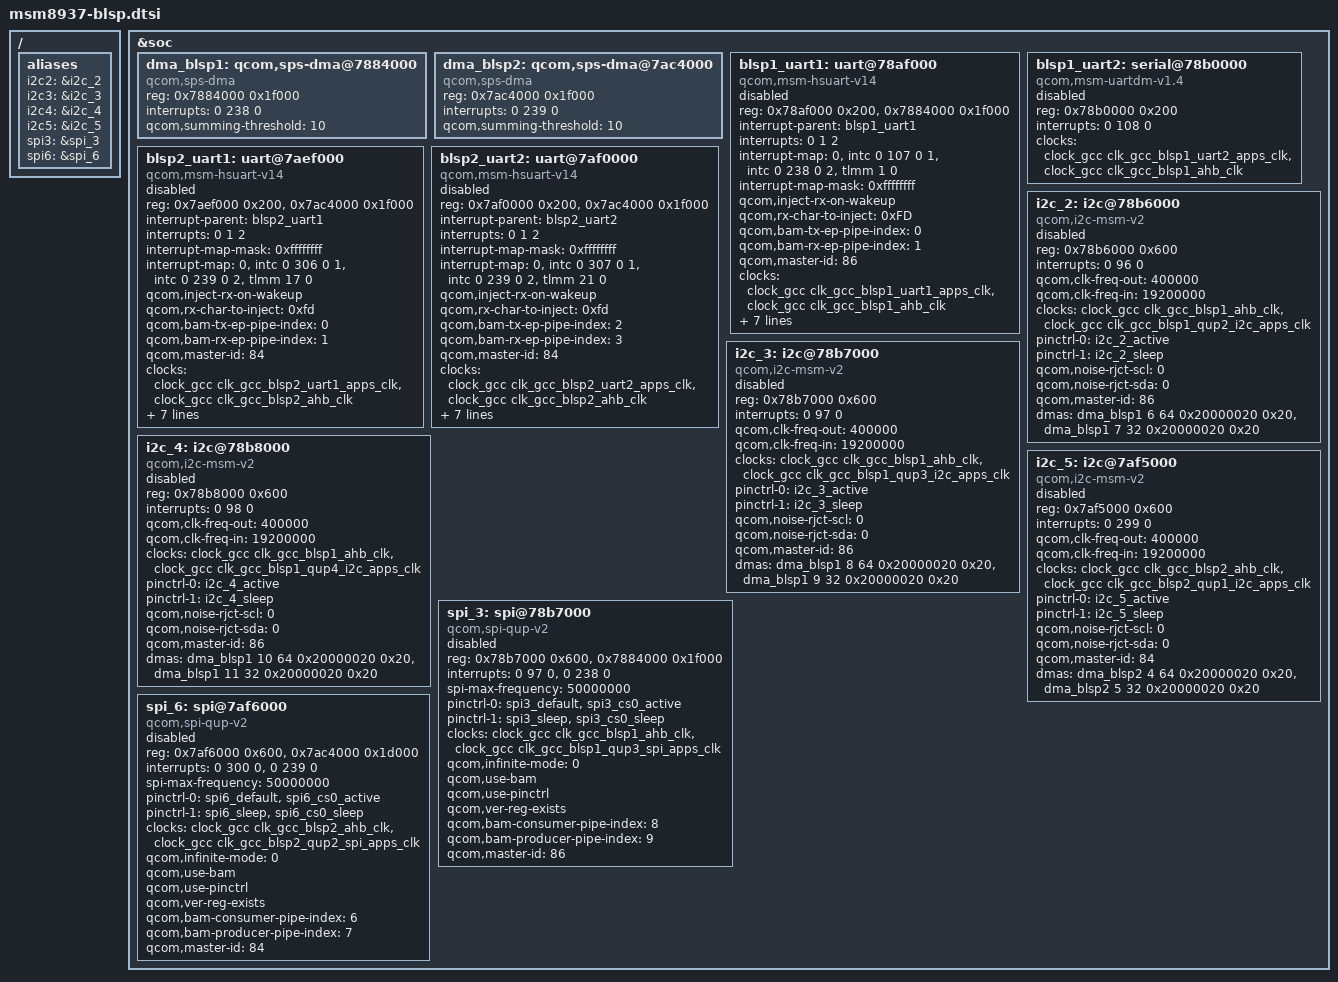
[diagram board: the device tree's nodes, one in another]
// SPDX-License-Identifier: GPL-2.0
/ {
	aliases {
		i2c2 = &i2c_2;
		i2c3 = &i2c_3;
		i2c4 = &i2c_4;
        i2c5 = &i2c_5;
        spi3 = &spi_3;
		spi6 = &spi_6;
	};
};

&soc {
	dma_blsp1: qcom,sps-dma@7884000 { /* BLSP1 */
		#dma-cells = <4>;
		compatible = "qcom,sps-dma";
		reg = <0x7884000 0x1f000>;
		interrupts = <0 238 0>;
		qcom,summing-threshold = <10>;
	};

    dma_blsp2: qcom,sps-dma@7ac4000 { /* BLSP2 */
		#dma-cells = <4>;
		compatible = "qcom,sps-dma";
		reg = <0x7ac4000 0x1f000>;
		interrupts = <0 239 0>;
		qcom,summing-threshold = <10>;
	};

	blsp1_uart1: uart@78af000 { /* BLSP1 UART1 */
		compatible = "qcom,msm-hsuart-v14";
		#address-cells = <0>;
		#interrupt-cells = <1>;
		reg = <0x78af000 0x200>,
			<0x7884000 0x1f000>;
		reg-names = "core_mem", "bam_mem";
		interrupt-parent = <&blsp1_uart1>;
		interrupts = <0 1 2>;
		interrupt-names = "core_irq", "bam_irq", "wakeup_irq";
		interrupt-map = <0 &intc 0 107 0
				1 &intc 0 238 0
				2 &tlmm 1 0>;
		interrupt-map-mask = <0xffffffff>;

		qcom,inject-rx-on-wakeup;
		qcom,rx-char-to-inject = <0xFD>;

		qcom,bam-tx-ep-pipe-index = <0>;
		qcom,bam-rx-ep-pipe-index = <1>;
		qcom,master-id = <86>;
		clock-names = "core_clk", "iface_clk";
		clocks = <&clock_gcc clk_gcc_blsp1_uart1_apps_clk>,
			<&clock_gcc clk_gcc_blsp1_ahb_clk>;
		pinctrl-names = "sleep", "default";
		pinctrl-0 = <&blsp1_uart1_sleep>;
		pinctrl-1 = <&blsp1_uart1_active>;

		qcom,msm-bus,name = "blsp1_uart1";
		qcom,msm-bus,num-cases = <2>;
		qcom,msm-bus,num-paths = <1>;
		qcom,msm-bus,vectors-KBps =
				<86 512 0 0>,
				<86 512 500 800>;
		status = "disabled";
	};

    blsp1_uart2: serial@78b0000 { /* BLSP1 UART2 */
		compatible = "qcom,msm-uartdm-v1.4", "qcom,msm-uartdm";
		reg = <0x78b0000 0x200>;
		interrupts = <0 108 0>;
		clocks = <&clock_gcc clk_gcc_blsp1_uart2_apps_clk>,
			<&clock_gcc clk_gcc_blsp1_ahb_clk>;
		clock-names = "core", "iface";
		status = "disabled";
	};

	blsp2_uart1: uart@7aef000 {
		compatible = "qcom,msm-hsuart-v14";
		reg = <0x7aef000 0x200>,
			<0x7ac4000 0x1f000>;
		reg-names = "core_mem", "bam_mem";
		interrupt-names = "core_irq", "bam_irq", "wakeup_irq";
		#address-cells = <0>;
		interrupt-parent = <&blsp2_uart1>;
		interrupts = <0 1 2>;
		#interrupt-cells = <1>;
		interrupt-map-mask = <0xffffffff>;
		interrupt-map = <0 &intc 0 306 0
				1 &intc 0 239 0
				2 &tlmm 17 0>;

		qcom,inject-rx-on-wakeup;
		qcom,rx-char-to-inject = <0xfd>;

		qcom,bam-tx-ep-pipe-index = <0>;
		qcom,bam-rx-ep-pipe-index = <1>;
		qcom,master-id = <84>;
		clock-names = "core_clk", "iface_clk";
		clocks = <&clock_gcc clk_gcc_blsp2_uart1_apps_clk>,
				<&clock_gcc clk_gcc_blsp2_ahb_clk>;
		pinctrl-names = "sleep", "default";
		pinctrl-0 = <&blsp2_uart1_sleep>;
		pinctrl-1 = <&blsp2_uart1_active>;
		qcom,msm-bus,name = "blsp2_uart1";
		qcom,msm-bus,num-cases = <2>;
		qcom,msm-bus,num-paths = <1>;
		qcom,msm-bus,vectors-KBps =
				<84 512 0 0>,
				<84 512 500 800>;
		status = "disabled";
	};

	blsp2_uart2: uart@7af0000 { /* BLSP2 UART2 */
		compatible = "qcom,msm-hsuart-v14";
		reg = <0x7af0000 0x200>,
			<0x7ac4000 0x1f000>;
		reg-names = "core_mem", "bam_mem";
		interrupt-names = "core_irq", "bam_irq", "wakeup_irq";
		#address-cells = <0>;
		interrupt-parent = <&blsp2_uart2>;
		interrupts = <0 1 2>;
		#interrupt-cells = <1>;
		interrupt-map-mask = <0xffffffff>;
		interrupt-map = <0 &intc 0 307 0
				1 &intc 0 239 0
				2 &tlmm 21 0>;

		qcom,inject-rx-on-wakeup;
		qcom,rx-char-to-inject = <0xfd>;

		qcom,bam-tx-ep-pipe-index = <2>;
		qcom,bam-rx-ep-pipe-index = <3>;
		qcom,master-id = <84>;
		clock-names = "core_clk", "iface_clk";
		clocks = <&clock_gcc clk_gcc_blsp2_uart2_apps_clk>,
				<&clock_gcc clk_gcc_blsp2_ahb_clk>;
		pinctrl-names = "sleep", "default";
		pinctrl-0 = <&blsp2_uart2_sleep>;
		pinctrl-1 = <&blsp2_uart2_active>;
		qcom,msm-bus,name = "blsp2_uart2";
		qcom,msm-bus,num-cases = <2>;
		qcom,msm-bus,num-paths = <1>;
		qcom,msm-bus,vectors-KBps =
				<84 512 0 0>,
				<84 512 500 800>;
		status = "disabled";
	};

    i2c_2: i2c@78b6000 { /* BLSP1 QUP2 */
		compatible = "qcom,i2c-msm-v2";
		#address-cells = <1>;
		#size-cells = <0>;
		reg-names = "qup_phys_addr";
		reg = <0x78b6000 0x600>;
		interrupt-names = "qup_irq";
		interrupts = <0 96 0>;
		qcom,clk-freq-out = <400000>;
		qcom,clk-freq-in  = <19200000>;
		clock-names = "iface_clk", "core_clk";
		clocks = <&clock_gcc clk_gcc_blsp1_ahb_clk>,
			<&clock_gcc clk_gcc_blsp1_qup2_i2c_apps_clk>;
		pinctrl-names = "i2c_active", "i2c_sleep";
		pinctrl-0 = <&i2c_2_active>;
		pinctrl-1 = <&i2c_2_sleep>;
		qcom,noise-rjct-scl = <0>;
		qcom,noise-rjct-sda = <0>;
		qcom,master-id = <86>;
		dmas = <&dma_blsp1 6 64 0x20000020 0x20>,
			<&dma_blsp1 7 32 0x20000020 0x20>;
		dma-names = "tx", "rx";
		status = "disabled";
	};

	i2c_3: i2c@78b7000 { /* BLSP1 QUP3 */
		compatible = "qcom,i2c-msm-v2";
		#address-cells = <1>;
		#size-cells = <0>;
		reg-names = "qup_phys_addr";
		reg = <0x78b7000 0x600>;
		interrupt-names = "qup_irq";
		interrupts = <0 97 0>;
		qcom,clk-freq-out = <400000>;
		qcom,clk-freq-in  = <19200000>;
		clock-names = "iface_clk", "core_clk";
		clocks = <&clock_gcc clk_gcc_blsp1_ahb_clk>,
			<&clock_gcc clk_gcc_blsp1_qup3_i2c_apps_clk>;

		pinctrl-names = "i2c_active", "i2c_sleep";
		pinctrl-0 = <&i2c_3_active>;
		pinctrl-1 = <&i2c_3_sleep>;
		qcom,noise-rjct-scl = <0>;
		qcom,noise-rjct-sda = <0>;
		qcom,master-id = <86>;
		dmas = <&dma_blsp1 8 64 0x20000020 0x20>,
			<&dma_blsp1 9 32 0x20000020 0x20>;
		dma-names = "tx", "rx";
		status = "disabled";
	};

    i2c_4: i2c@78b8000 { /* BLSP1 QUP4 */
		compatible = "qcom,i2c-msm-v2";
		#address-cells = <1>;
		#size-cells = <0>;
		reg-names = "qup_phys_addr";
		reg = <0x78b8000 0x600>;
		interrupt-names = "qup_irq";
		interrupts = <0 98 0>;
		qcom,clk-freq-out = <400000>;
		qcom,clk-freq-in  = <19200000>;
		clock-names = "iface_clk", "core_clk";
		clocks = <&clock_gcc clk_gcc_blsp1_ahb_clk>,
			<&clock_gcc clk_gcc_blsp1_qup4_i2c_apps_clk>;
		pinctrl-names = "i2c_active", "i2c_sleep";
		pinctrl-0 = <&i2c_4_active>;
		pinctrl-1 = <&i2c_4_sleep>;
		qcom,noise-rjct-scl = <0>;
		qcom,noise-rjct-sda = <0>;
		qcom,master-id = <86>;
		dmas = <&dma_blsp1 10 64 0x20000020 0x20>,
		<&dma_blsp1 11 32 0x20000020 0x20>;
		dma-names = "tx", "rx";
		status = "disabled";
	};

	i2c_5: i2c@7af5000 { /* BLSP2 QUP1 */
		compatible = "qcom,i2c-msm-v2";
		#address-cells = <1>;
		#size-cells = <0>;
		reg-names = "qup_phys_addr";
		reg = <0x7af5000 0x600>;
		interrupt-names = "qup_irq";
		interrupts = <0 299 0>;
		qcom,clk-freq-out = <400000>;
		qcom,clk-freq-in  = <19200000>;
		clock-names = "iface_clk", "core_clk";
		clocks = <&clock_gcc clk_gcc_blsp2_ahb_clk>,
			<&clock_gcc clk_gcc_blsp2_qup1_i2c_apps_clk>;

		pinctrl-names = "i2c_active", "i2c_sleep";
		pinctrl-0 = <&i2c_5_active>;
		pinctrl-1 = <&i2c_5_sleep>;
		qcom,noise-rjct-scl = <0>;
		qcom,noise-rjct-sda = <0>;
		qcom,master-id = <84>;
		dmas = <&dma_blsp2 4 64 0x20000020 0x20>,
			<&dma_blsp2 5 32 0x20000020 0x20>;
		dma-names = "tx", "rx";
		status = "disabled";
	};

    spi_3: spi@78b7000 { /* BLSP1 QUP3 */
		compatible = "qcom,spi-qup-v2";
		#address-cells = <1>;
		#size-cells = <0>;
		reg-names = "spi_physical", "spi_bam_physical";
		reg = <0x78b7000 0x600>,
			<0x7884000 0x1f000>;
		interrupt-names = "spi_irq", "spi_bam_irq";
		interrupts = <0 97 0>, <0 238 0>;
		spi-max-frequency = <50000000>;
		pinctrl-names = "spi_default", "spi_sleep";
		pinctrl-0 = <&spi3_default &spi3_cs0_active>;
		pinctrl-1 = <&spi3_sleep &spi3_cs0_sleep>;
		clocks = <&clock_gcc clk_gcc_blsp1_ahb_clk>,
			<&clock_gcc clk_gcc_blsp1_qup3_spi_apps_clk>;
		clock-names = "iface_clk", "core_clk";
		qcom,infinite-mode = <0>;
		qcom,use-bam;
		qcom,use-pinctrl;
		qcom,ver-reg-exists;
		qcom,bam-consumer-pipe-index = <8>;
		qcom,bam-producer-pipe-index = <9>;
		qcom,master-id = <86>;
		status = "disabled";
	};

    spi_6: spi@7af6000 { /* BLSP2 QUP2 */
		compatible = "qcom,spi-qup-v2";
		#address-cells = <1>;
		#size-cells = <0>;
		reg-names = "spi_physical", "spi_bam_physical";
		reg = <0x7af6000 0x600>,
			<0x7ac4000 0x1d000>;
		interrupt-names = "spi_irq", "spi_bam_irq";
		interrupts = <0 300 0>, <0 239 0>;
		spi-max-frequency = <50000000>;
		pinctrl-names = "spi_default", "spi_sleep";
		pinctrl-0 = <&spi6_default &spi6_cs0_active>;
		pinctrl-1 = <&spi6_sleep &spi6_cs0_sleep>;
		clocks = <&clock_gcc clk_gcc_blsp2_ahb_clk>,
			<&clock_gcc clk_gcc_blsp2_qup2_spi_apps_clk>;
		clock-names = "iface_clk", "core_clk";
		qcom,infinite-mode = <0>;
		qcom,use-bam;
		qcom,use-pinctrl;
		qcom,ver-reg-exists;
		qcom,bam-consumer-pipe-index = <6>;
		qcom,bam-producer-pipe-index = <7>;
		qcom,master-id = <84>;
		status = "disabled";
	};
};
